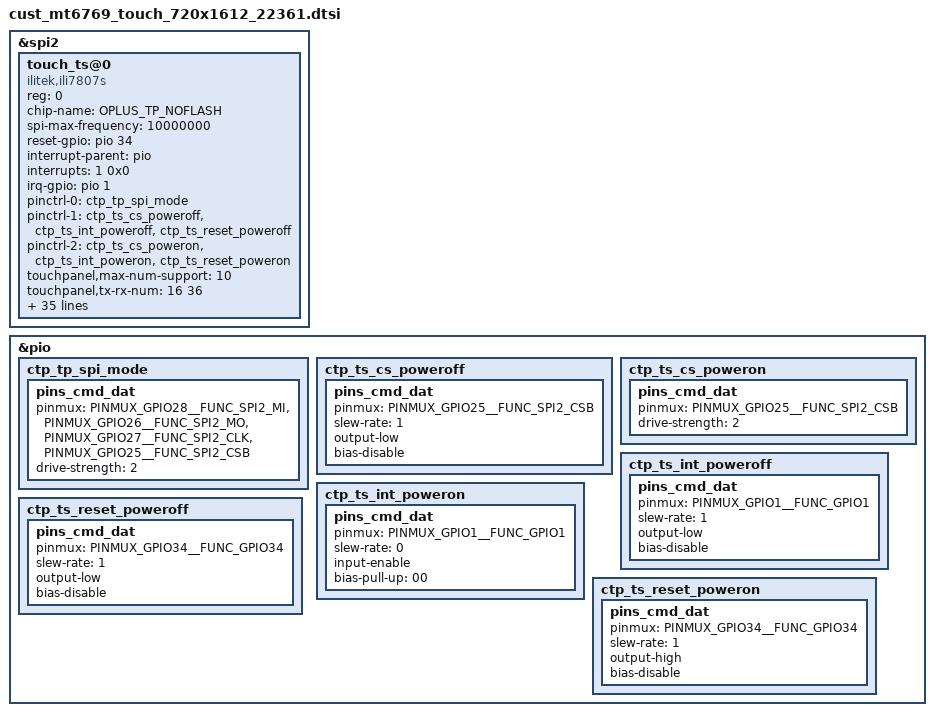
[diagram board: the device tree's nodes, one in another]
//PDX-License-Identifier: GPL-2.0+
/*
 * Copyright (c) 2019 MediaTek Inc.
 *
 */

&spi2 {
    #address-cells = <1>;
    #size-cells = <0>;
    status = "ok";

	touch_ts@0 {
		compatible = "ilitek,ili7807s";
		reg = <0>;
		chip-name = "OPLUS_TP_NOFLASH";
		status = "ok";

		spi-max-frequency = <10000000>;    //4800000,9600000,10000000,15000000,19200000
		reset-gpio = <&pio 34 0x00>;
		interrupt-parent = <&pio>;
		interrupts = <1 0x0>;
		irq-gpio = <&pio 1 0x2002>;

		/*tp-pinctrl*/
		pinctrl-names = "default", "pin_set_low", "pin_set_high";
		pinctrl-0 = <&ctp_tp_spi_mode>;
		pinctrl-1 = <&ctp_ts_cs_poweroff &ctp_ts_int_poweroff &ctp_ts_reset_poweroff>;
		pinctrl-2 = <&ctp_ts_cs_poweron  &ctp_ts_int_poweron  &ctp_ts_reset_poweron>;

		touchpanel,max-num-support = <10>;
		touchpanel,tx-rx-num = <16 36>;
		touchpanel,panel-coords = <2880 6448>;
		touchpanel,display-coords = <720 1612>;
		touchpanel,touchmajor-limit = <0 54>;
		touchpanel,button-type = <4>;
		touchpanel.button-TRx = <0 0>;

		platform_support_project = <22361 22362 22363 22364 22365 22366 22367 22368>;
		platform_support_project_dir = <22361 22361 22361 22361 22361 22361 22361 22361>;
		platform_support_project_commandline = "default_commandline","default_commandline","default_commandline","default_commandline","default_commandline","default_commandline","default_commandline","default_commandline";

		touchpanel,smooth-level = <255 5 4 3 2 1>;
		touchpanel,sensitive-level = <255 1 2 3 4 5>;
		touchpanel,single-optimized-time = <8>;
		touchpanel,msecs-to-jiffies-time = <500>;

		incell_screen;
		fw_edge_limit_support;
		black_gesture_support;
		charger_pump_support;
		esd_handle_support;
		black_gesture_test_support;
		noflash_support;
		smart_gesture_support;
		fw_update_app_support;
		pressure_report_support;
		new_set_irq_wake_support;
		lcd_trigger_load_tp_fw_support;
		fw_update_in_probe_with_headfile;
		health_monitor_v2_support;
		exception_upload_support;
		irq_need_dev_resume_ok;
		shutdown_support;
	};
};

&pio {
	ctp_tp_spi_mode:ctp_tp_spi_mode{
		pins_cmd_dat {
			pinmux = <PINMUX_GPIO28__FUNC_SPI2_MI>,
				<PINMUX_GPIO26__FUNC_SPI2_MO>,
				<PINMUX_GPIO27__FUNC_SPI2_CLK>,
				<PINMUX_GPIO25__FUNC_SPI2_CSB>;
			drive-strength = <2>;
		};
	};
	ctp_ts_cs_poweroff: ctp_ts_cs_poweroff {
		pins_cmd_dat {
			pinmux = <PINMUX_GPIO25__FUNC_SPI2_CSB>;
			slew-rate = <1>;
			output-low;
			bias-disable;
		};
	};
	ctp_ts_cs_poweron: ctp_ts_cs_poweron {
		pins_cmd_dat {
			pinmux = <PINMUX_GPIO25__FUNC_SPI2_CSB>;
			drive-strength = <2>;
		};
	};
	ctp_ts_int_poweroff: ctp_ts_int_poweroff {
		pins_cmd_dat {
			pinmux = <PINMUX_GPIO1__FUNC_GPIO1>;
			slew-rate = <1>;
			output-low;
			bias-disable;
		};
	};
	ctp_ts_int_poweron: ctp_ts_int_poweron {
		pins_cmd_dat {
			pinmux = <PINMUX_GPIO1__FUNC_GPIO1>;
			slew-rate = <0>;
			input-enable;
			bias-pull-up = <00>;
		};
	};
	ctp_ts_reset_poweroff: ctp_ts_reset_poweroff {
		pins_cmd_dat {
			pinmux = <PINMUX_GPIO34__FUNC_GPIO34>;
			slew-rate = <1>;
			output-low;
			bias-disable;
		};
	};

	ctp_ts_reset_poweron: ctp_ts_reset_poweron {
		pins_cmd_dat {
			pinmux = <PINMUX_GPIO34__FUNC_GPIO34>;
			slew-rate = <1>;
			output-high;
			bias-disable;
		};
	};
};

/* TOUCH end */
